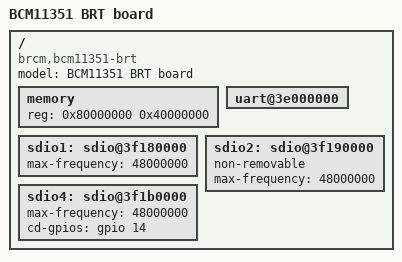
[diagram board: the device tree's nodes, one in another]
/*
 * Copyright (C) 2012 Broadcom Corporation
 *
 * This program is free software; you can redistribute it and/or
 * modify it under the terms of the GNU General Public License as
 * published by the Free Software Foundation version 2.
 *
 * This program is distributed "as is" WITHOUT ANY WARRANTY of any
 * kind, whether express or implied; without even the implied warranty
 * of MERCHANTABILITY or FITNESS FOR A PARTICULAR PURPOSE.  See the
 * GNU General Public License for more details.
 */

/dts-v1/;

#include "bcm11351.dtsi"

/ {
	model = "BCM11351 BRT board";
	compatible = "brcm,bcm11351-brt", "brcm,bcm11351";

	memory {
		reg = <0x80000000 0x40000000>; /* 1 GB */
	};

	uart@3e000000 {
		status = "okay";
	};

	sdio1: sdio@3f180000 {
		max-frequency = <48000000>;
		status = "okay";
	};

	sdio2: sdio@3f190000 {
		non-removable;
		max-frequency = <48000000>;
		status = "okay";
	};

	sdio4: sdio@3f1b0000 {
		max-frequency = <48000000>;
		cd-gpios = <&gpio 14 0>;
		status = "okay";
	};


};
